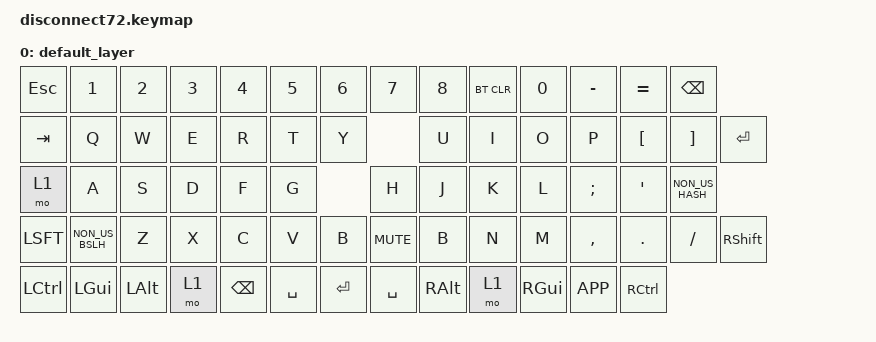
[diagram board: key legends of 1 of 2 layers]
#include <behaviors.dtsi>
#include <dt-bindings/zmk/keys.h>
#include <dt-bindings/zmk/bt.h>
#include <dt-bindings/zmk/ext_power.h>

/ {

	keymap {
		compatible = "zmk,keymap";

		default_layer {
// --------------------------------------------------------------------------------------------------------------------------
// |  ESC   |  1  |  2  |  3   |  4   |  5   |  6   |               |  7   |  8    |  9    |  0   |   +   |   ´   | BSPC       |
// |  TAB   |  Q  |  W  |  E   |  R   |  T   |                      |  Y   |  U    |  I    |  O   |   P   |   Å   | ¨  | ENTER |
// |  MO    |  A  |  S  |  D   |  F   |  G   |                      |  H   |  J    |  K    |  L   |   Ö   |   Ä   | *     |    |
// | SHIFT  | <   |  Z  |  X   |  C   |  V   |  B   |        |  B   |  N   |  M    |  ,    |  .   |   -   |     SHIFT          |
// | CTRL   | GUI | ALT | GUI  | MO   |                             | SPCE         | ALTGR | MO   | GUI  |  OPT  | CTRL        |
//                                    | BSPC |
//                                     | SPACE| ENTER|		
            bindings = <
&kp ESC     &kp N1          &kp N2      &kp N3  &kp N4  	&kp N5  	&kp N6          &kp N7  &kp N8  &bt BT_CLR      &kp N0      &kp MINUS   &kp EQUAL   &kp BSPC    
&kp TAB     &kp Q           &kp W       &kp E   &kp R   	&kp T                   	&kp Y   &kp U   &kp I       &kp O       &kp P       &kp LBKT    &kp RBKT   &kp RET 
&mo 1       &kp A           &kp S       &kp D   &kp F   	&kp G                  		&kp H   &kp J   &kp K       &kp L       &kp SEMI    &kp SQT     &kp NON_US_HASH 
&kp LSFT    &kp NON_US_BSLH &kp Z       &kp X   &kp C   	&kp V   	&kp B           &kp C_MUTE   	&kp B   	&kp N   	&kp M   	&kp COMMA   &kp DOT    &kp FSLH    &kp RSHIFT     
&kp LCTRL   &kp LGUI        &kp LALT    &mo 1   &kp BSPC 	&kp SPACE 	&kp RET         &kp SPACE       &kp RALT    &mo 1       &kp RGUI    &kp K_APP   &kp RCTRL                                 	
			>;

			//sensor-bindings = <&inc_dec_kp C_VOL_UP C_VOL_DN &inc_dec_kp PG_UP PG_DN>;
		};

		lower_layer {
			bindings = <
&kp GRAVE   &kp F1          &kp  F2     &kp  F3  &kp  F4  	&kp  F5  		&kp  F6      	&kp  F7  &kp  F8  &kp  F9     &kp  F10      &kp F11     &kp F12       &kp DELETE    
&trans      &trans          &trans      &trans   &trans   	&trans                			&trans   &trans   &trans      &trans        &trans      &trans        &kp INSERT      &trans 
&trans      &trans          &trans      &trans   &trans   	&trans                			&trans   &trans   &trans      &trans        &trans      &trans        &trans 
&trans      &trans          &trans      &trans   &trans   	&trans   		&trans       	&trans   &trans   &trans      &trans        &trans      &kp UP        &trans     
&trans      &trans          &trans      &trans   &bt BT_CLR &bt BT_SEL 0 	&bt BT_SEL 1    &trans            &trans      &kp LEFT      &kp DOWN  	&kp RIGHT     &kp RCTRL
                                                                                                          	
			>;

			//sensor-bindings = <&inc_dec_kp C_VOL_UP C_VOL_DN &inc_dec_kp PG_UP PG_DN>;

			
		};
	};
};
